# cslr_dtf register map
Vendor: Texas Instruments
Peripheral module from a debugger description file.
Registers are 32-bit, access not given, reset 0x0 unless marked. A register's access mark holds for its fields unless they carry their own. Offsets are as the file gives them; lines under a group give offsets from that group; [hi:lo] are bit positions; {n}, {i} and the like mark numbered series; 'fields as' and 'values as' point back to an identical list; <NAME> marks a mode.

## DTF — DTF(DSP Trace Formatter)
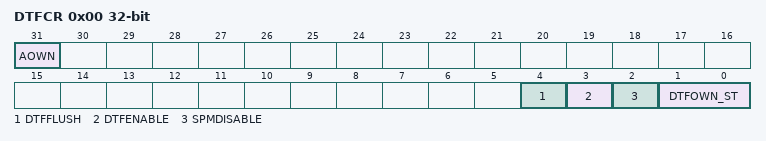
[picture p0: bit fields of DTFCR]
0x00 DTFCR — DTFCR(All_Purpose DTF Control Register)
  [31] AOWN rw — DTF Ownership
    0=APP; 1=EMU
  [4] DTFFLUSH wo — DTF Flush provides a mechanism to flush a partially filled trace word.
  [3] DTFENABLE rw
    1=ENABLE
  [2] SPMDISABLE rw — Disable trace output to Static_Pin Merge.
    1=DISABLE; 0=ENABLE
  [1:0] DTFOWN_ST rw — DTF Ownership State Control
